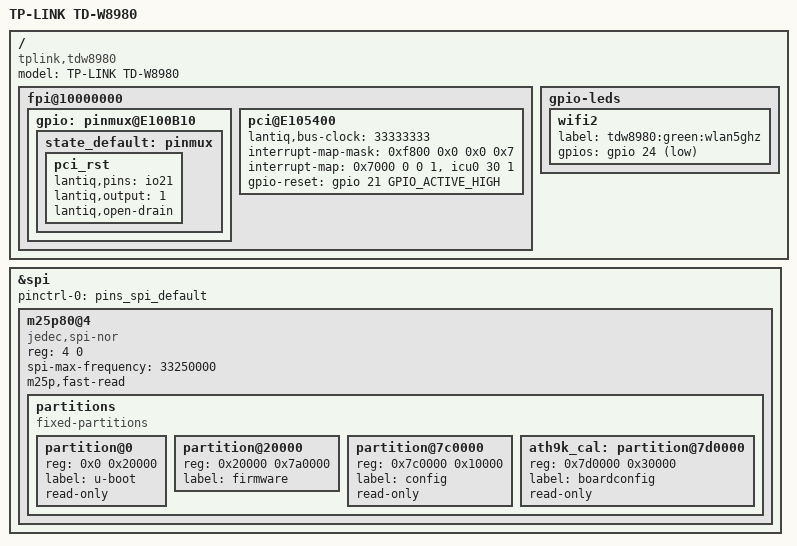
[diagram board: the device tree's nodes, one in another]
/dts-v1/;

#include "TDW89X0.dtsi"

/ {
	compatible = "tplink,tdw8980", "tplink,tdw89x0", "lantiq,xway", "lantiq,vr9";
	model = "TP-LINK TD-W8980";

	fpi@10000000 {
		gpio: pinmux@E100B10 {
			state_default: pinmux {
				pci_rst {
					lantiq,pins = "io21";
					lantiq,output = <1>;
					lantiq,open-drain;
				};
			};
		};

		pci@E105400 {
			status = "okay";
			lantiq,bus-clock = <33333333>;
			interrupt-map-mask = <0xf800 0x0 0x0 0x7>;
			interrupt-map = <0x7000 0 0 1 &icu0 30 1>;
			gpio-reset = <&gpio 21 GPIO_ACTIVE_HIGH>;
		};
	};

	gpio-leds {
		wifi2 {
			label = "tdw8980:green:wlan5ghz";
			gpios = <&gpio 24 GPIO_ACTIVE_LOW>;
		};
	};
};

&spi {
	pinctrl-names = "default";
	pinctrl-0 = <&pins_spi_default>;

	status = "ok";

	m25p80@4 {
		#address-cells = <1>;
		#size-cells = <1>;
		compatible = "jedec,spi-nor";
		reg = <4 0>;
		spi-max-frequency = <33250000>;
		m25p,fast-read;

		partitions {
			compatible = "fixed-partitions";
			#address-cells = <1>;
			#size-cells = <1>;

			partition@0 {
				reg = <0x0 0x20000>;
				label = "u-boot";
				read-only;
			};

			partition@20000 {
				reg = <0x20000 0x7a0000>;
				label = "firmware";
			};

			partition@7c0000 {
				reg = <0x7c0000 0x10000>;
				label = "config";
				read-only;
			};

			ath9k_cal: partition@7d0000 {
				reg = <0x7d0000 0x30000>;
				label = "boardconfig";
				read-only;
			};
		};
	};
};
